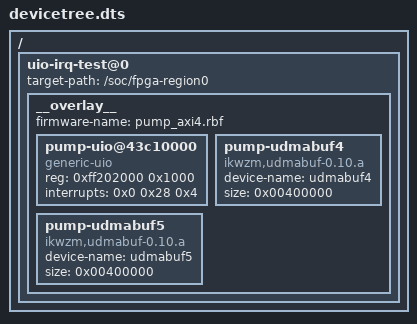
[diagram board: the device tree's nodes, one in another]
/dts-v1/;
/ {
	uio-irq-test@0 {
		target-path = "/soc/fpga-region0";
		#address-cells = <0x1>;
		#size-cells = <0x1>;
		
		__overlay__ {
			#address-cells = <0x1>;
			#size-cells = <0x1>;

			firmware-name = "pump_axi4.rbf";
			
			pump-uio@43c10000 {
				compatible = "generic-uio";
				reg = <0xff202000 0x1000>;
				interrupts = <0x0 0x28 0x4>;
	                };

			pump-udmabuf4 {
				compatible  = "ikwzm,udmabuf-0.10.a";
				device-name = "udmabuf4";
				size = <0x00400000>;
	                };

			pump-udmabuf5 {
				compatible = "ikwzm,udmabuf-0.10.a";
				device-name = "udmabuf5";
				size = <0x00400000>;
			};
                };
	} ;
} ;
